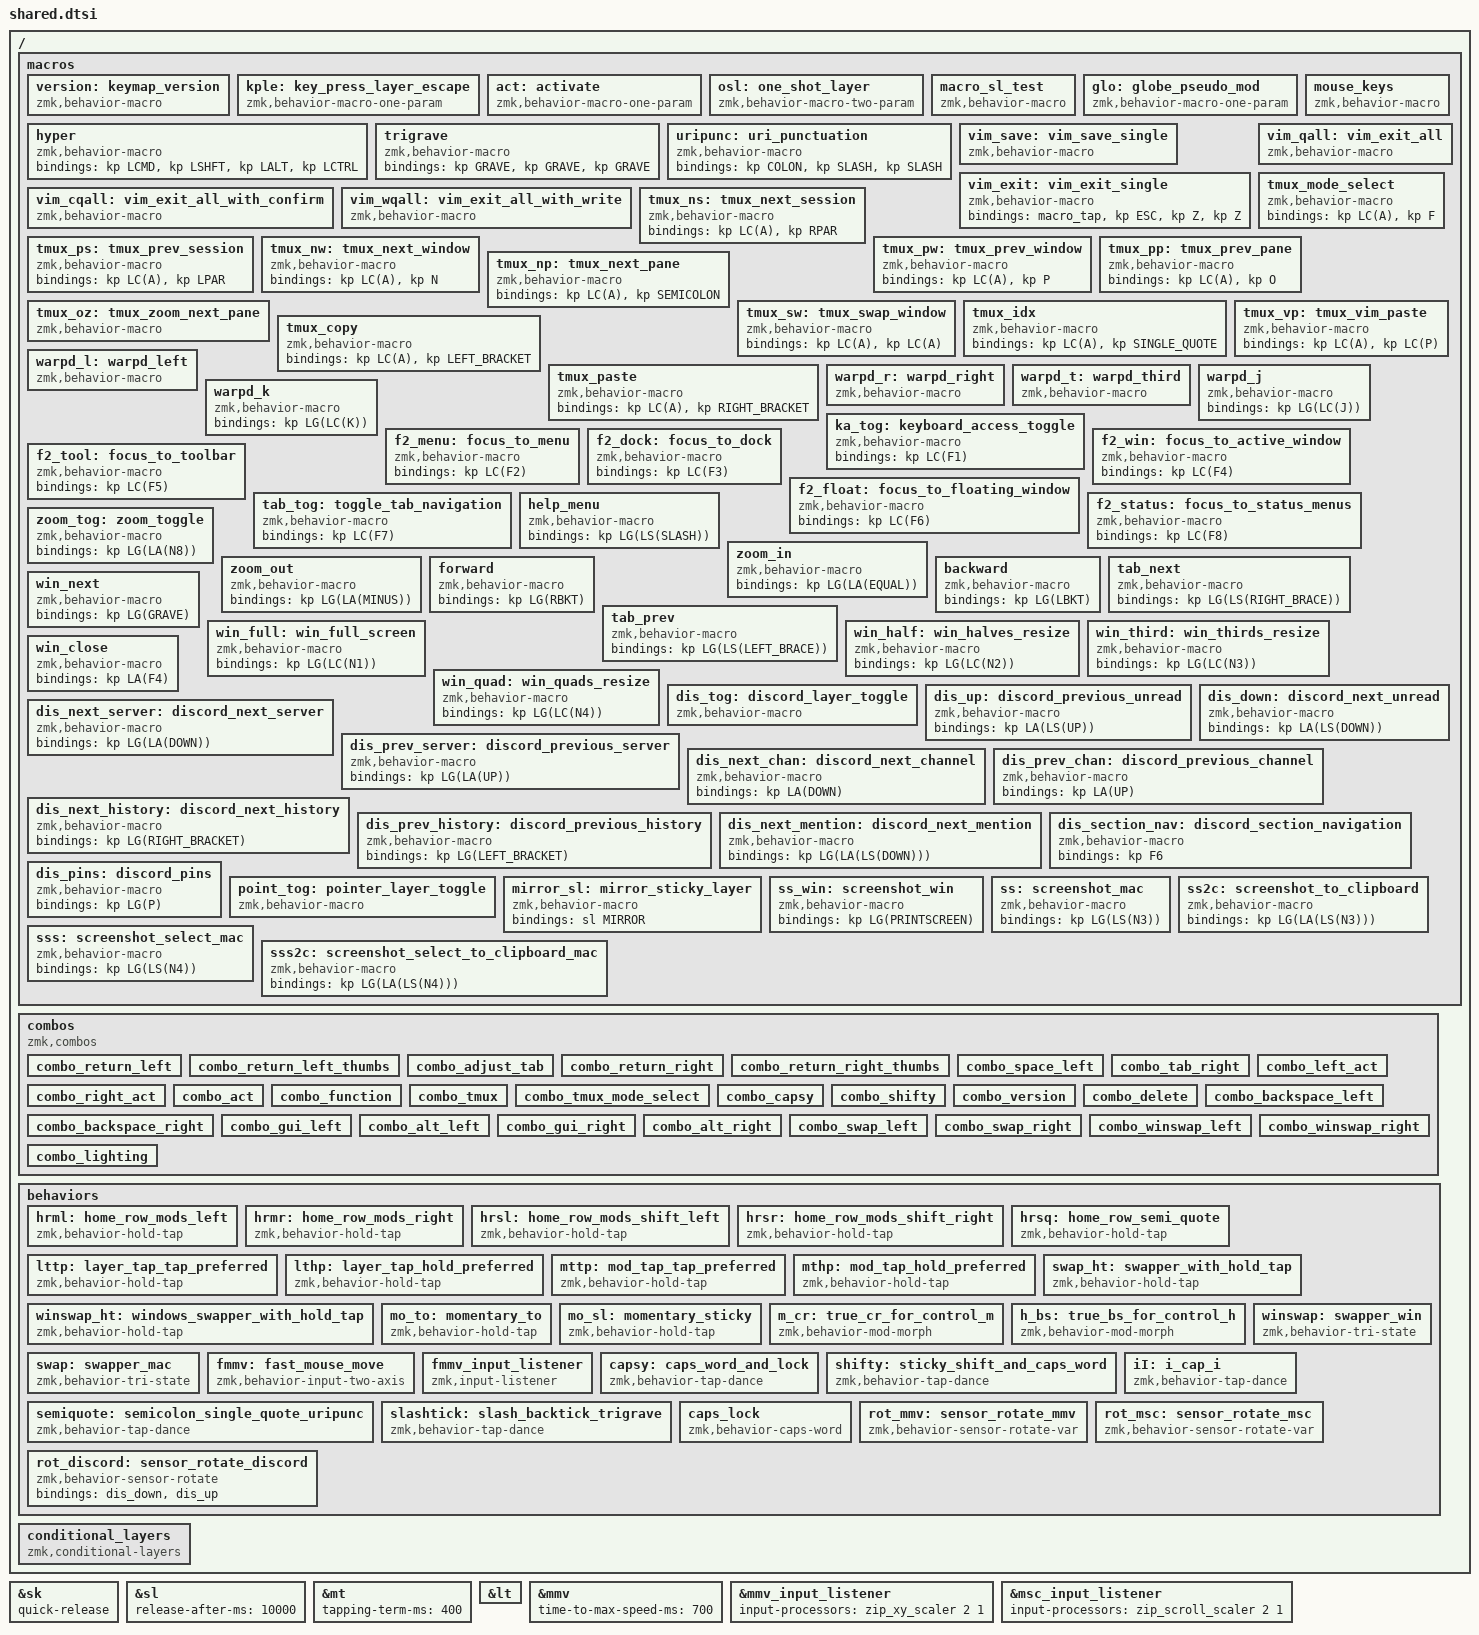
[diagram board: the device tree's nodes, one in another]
#define VER_PATCH N6
#define VER_MINOR N7
#define VER_MAJOR N3

// DEFINES {{{
#define HYPER(X) LG(LA(LC(LS(X))))
#define DISCORD_ACT LC(LS(N))
#define CARD_ACT     HYPER(A)
#define CARD_FUNC    HYPER(F)
#define CARD_DISCORD HYPER(D)
#define CARD_POINTER HYPER(P)
#define CARD_DEACTIVATE HYPER(DELETE)
#define LEFT_POSITIONS  0 1 2 3 4 5 12 13 14 15 16 17 24 25 26 27 28 29 36 37 38
#define RIGHT_POSITIONS 6 7 8 9 10 11 18 19 20 21 22 23 30 31 32 33 34 35 39 40 41

// Timing Defaults

#define CAPS_COMBO_MS 125
#define VERT_COMBO_MS 75
#define TRI_COMBO_MS  50
#define ROLL_COMBO_MS 25

// Layers
#define DEFAULT   0
#define GAMING    1
#define SYMBOLS   2
#define LNUM      3
#define NUMPAD    4
#define MEDIA     5
#define OUTPUT    6
#define ADJUST    7
#define LIGHTING  8
#define DISCORD   9
#define POINTER   10
#define MIRROR    11
#define WIN_LEFT  12
#define WIN_RIGHT 13
#define ACT       14
#define FUNCTION  15
// }}}

#include <input/processors.dtsi>

/* Key Positions
╭────────────────────────╮ ╭────────────────────────╮
│  0   1   2   3   4   5 │ │  6   7   8   9  10  11 │
│ 12  13  14  15  16  17 │ │ 18  19  20  21  22  23 │
│ 24  25  26  27  28  29 │ │ 30  31  32  33  34  35 │
╰───────────╮ 36  37  38 │ │ 39  40  41 ╭───────────╯
            ╰────────────╯ ╰────────────╯
*/
// CONFIG {{{
&sk {
    quick-release;
};

&sl {
    release-after-ms = <10000>;
};

&mt {
    tapping-term-ms = <400>;
};

&lt {
    tapping-term-ms = <400>;
    quick-tap-ms = <250>;
};

&mmv {
    time-to-max-speed-ms = <700>;
};

&mmv_input_listener {
    input-processors = <&zip_xy_scaler 2 1>;
};

&msc_input_listener {
    input-processors = <&zip_scroll_scaler 2 1>;
};

// }}}
/ {
// MACROS LAYERS {{{
    macros {
        version: keymap_version {
            compatible = "zmk,behavior-macro";
            #binding-cells = <0>;
            bindings = <&kp VER_MAJOR &kp DOT &kp VER_MINOR &kp VER_PATCH>;
        };
        kple: key_press_layer_escape {
            compatible = "zmk,behavior-macro-one-param";
            #binding-cells = <1>;
            bindings
                = <&macro_tap &kp CARD_DEACTIVATE>
                , <&macro_tap &to DEFAULT>
                , <&macro_param_1to1>
                , <&macro_tap &kp MACRO_PLACEHOLDER>
                ;
        };
        act: activate {
            compatible = "zmk,behavior-macro-one-param";
            #binding-cells = <1>;
            bindings
                = <&macro_tap &kp CARD_DEACTIVATE>
                , <&macro_tap &to DEFAULT>
                , <&macro_press &kp LSHFT &kp LCTRL>
                , <&macro_param_1to1>
                , <&macro_tap &kp MACRO_PLACEHOLDER>
                , <&macro_release &kp LSHFT &kp LCTRL>
                ;
        };
        osl: one_shot_layer {
            compatible = "zmk,behavior-macro-two-param";
            #binding-cells = <2>;
            bindings
                = <&macro_tap &kp CARD_DEACTIVATE>
                , <&macro_param_1to1>
                , <&macro_tap &kp MACRO_PLACEHOLDER>
                , <&macro_param_2to1>
                , <&macro_tap &sl MACRO_PLACEHOLDER>
                ;
        };
        macro_sl_test: macro_sl_test {
            compatible = "zmk,behavior-macro";
            #binding-cells = <0>;
            bindings
                = <&macro_tap &kp SINGLE_QUOTE>
                , <&macro_tap &sl NUMPAD>
                , <&macro_pause_for_release>
                , <&macro_tap &kp SINGLE_QUOTE>
                ;
        };
        glo: globe_pseudo_mod {
            compatible = "zmk,behavior-macro-one-param";
            #binding-cells = <1>;
            bindings
                = <&macro_press &kp GLOBE>
                , <&macro_param_1to1>
                , <&macro_tap &kp MACRO_PLACEHOLDER>
                , <&macro_release &kp GLOBE>
                ;
        };
        hyper: hyper {
            compatible = "zmk,behavior-macro";
            #binding-cells = <0>;
            bindings = <&kp LCMD &kp LSHFT &kp LALT &kp LCTRL>;
        };
        trigrave: trigrave {
            compatible = "zmk,behavior-macro";
            #binding-cells = <0>;
            bindings = <&kp GRAVE &kp GRAVE &kp GRAVE>;
        };
        uripunc: uri_punctuation {
            compatible = "zmk,behavior-macro";
            #binding-cells = <0>;
            bindings = <&kp COLON &kp SLASH &kp SLASH>;
        };
        mouse_keys: mouse_keys {
            compatible = "zmk,behavior-macro";
            #binding-cells = <0>;
            bindings = <&kp LALT &kp LALT &kp LALT &kp LALT &kp LALT>;
        };
        vim_save: vim_save_single {
            compatible = "zmk,behavior-macro";
            #binding-cells = <0>;
            bindings =
                <&macro_tap>,
                <&kp ESC &kp COLON &kp W &kp RETURN>;
        };
        vim_exit: vim_exit_single {
            compatible = "zmk,behavior-macro";
            #binding-cells = <0>;
            bindings =
                <&macro_tap>,
                <&kp ESC &kp Z &kp Z>;
        };
        vim_qall: vim_exit_all {
            compatible = "zmk,behavior-macro";
            #binding-cells = <0>;
            bindings =
                <&macro_tap>,
                <&kp ESC &kp COLON &kp Q &kp A &kp L &kp RETURN>;
        };
        vim_cqall: vim_exit_all_with_confirm {
            compatible = "zmk,behavior-macro";
            #binding-cells = <0>;
            bindings =
                <&macro_tap>,
                <&kp ESC &kp COLON &kp C &kp O &kp N &kp F &kp SPACE &kp Q &kp A &kp L &kp RETURN>;
        };
        vim_wqall: vim_exit_all_with_write {
            compatible = "zmk,behavior-macro";
            #binding-cells = <0>;
            bindings =
                <&macro_tap>,
                <&kp ESC &kp COLON &kp W &kp Q &kp A &kp L &kp RETURN>;
        };
        tmux_mode_select: tmux_mode_select {
            compatible = "zmk,behavior-macro";
            #binding-cells = <0>;
            bindings = <&kp LC(A) &kp F>;
        };
        tmux_ns: tmux_next_session {
            compatible = "zmk,behavior-macro";
            #binding-cells = <0>;
            bindings = <&kp LC(A) &kp RPAR>;
        };
        tmux_ps: tmux_prev_session {
            compatible = "zmk,behavior-macro";
            #binding-cells = <0>;
            bindings = <&kp LC(A) &kp LPAR>;
        };
        tmux_nw: tmux_next_window {
            compatible = "zmk,behavior-macro";
            #binding-cells = <0>;
            bindings = <&kp LC(A) &kp N>;
        };
        tmux_pw: tmux_prev_window {
            compatible = "zmk,behavior-macro";
            #binding-cells = <0>;
            bindings = <&kp LC(A) &kp P>;
        };
        tmux_pp: tmux_prev_pane {
            compatible = "zmk,behavior-macro";
            #binding-cells = <0>;
            bindings = <&kp LC(A) &kp O>;
        };
        tmux_np: tmux_next_pane {
            compatible = "zmk,behavior-macro";
            #binding-cells = <0>;
            bindings = <&kp LC(A) &kp SEMICOLON>;
        };
        tmux_oz: tmux_zoom_next_pane {
            compatible = "zmk,behavior-macro";
            #binding-cells = <0>;
            bindings
                = <&macro_wait_time 35>
                , <&macro_tap_time 25>
                , <&kp LC(A) &kp O>
                , <&kp LC(A) &kp Z>
                ;
        };
        tmux_sw: tmux_swap_window {
            compatible = "zmk,behavior-macro";
            #binding-cells = <0>;
            bindings
                = <&kp LC(A) &kp LC(A)>
                ;
        };
        tmux_idx: tmux_idx {
            compatible = "zmk,behavior-macro";
            #binding-cells = <0>;
            bindings
                = <&kp LC(A) &kp SINGLE_QUOTE>
                ;
        };
        tmux_copy: tmux_copy {
            compatible = "zmk,behavior-macro";
            #binding-cells = <0>;
            bindings
                = <&kp LC(A) &kp LEFT_BRACKET>
                ;
        };
        tmux_paste: tmux_paste {
            compatible = "zmk,behavior-macro";
            #binding-cells = <0>;
            bindings
                = <&kp LC(A) &kp RIGHT_BRACKET>
                ;
        };
        tmux_vp: tmux_vim_paste {
            compatible = "zmk,behavior-macro";
            #binding-cells = <0>;
            bindings
                = <&kp LC(A) &kp LC(P)>
                ;
        };
        warpd_l: warpd_left {
            compatible = "zmk,behavior-macro";
            #binding-cells = <0>;
            bindings = <&kple LG(LC(S)) &kp J &kp ESC &kp LG(LC(Y))>;
        };
        warpd_r: warpd_right {
            compatible = "zmk,behavior-macro";
            #binding-cells = <0>;
            bindings = <&kple LG(LC(S)) &kp K &kp ESC &kp LG(LC(Y))>;
        };
        warpd_t: warpd_third {
            compatible = "zmk,behavior-macro";
            #binding-cells = <0>;
            bindings = <&kple LG(LC(S)) &kp L &kp ESC &kp LG(LC(Y))>;
        };
        warpd_j: warpd_j {
            compatible = "zmk,behavior-macro";
            #binding-cells = <0>;
            bindings = <&kp LG(LC(J))>;
        };
        warpd_k: warpd_k {
            compatible = "zmk,behavior-macro";
            #binding-cells = <0>;
            bindings = <&kp LG(LC(K))>;
        };
        ka_tog: keyboard_access_toggle {
            compatible = "zmk,behavior-macro";
            #binding-cells = <0>;
            bindings = <&kp LC(F1)>;
        };
        f2_menu: focus_to_menu {
            compatible = "zmk,behavior-macro";
            #binding-cells = <0>;
            bindings = <&kp LC(F2)>;
        };
        f2_dock: focus_to_dock {
            compatible = "zmk,behavior-macro";
            #binding-cells = <0>;
            bindings = <&kp LC(F3)>;
        };
        f2_win: focus_to_active_window {
            compatible = "zmk,behavior-macro";
            #binding-cells = <0>;
            bindings = <&kp LC(F4)>;
        };
        f2_tool: focus_to_toolbar {
            compatible = "zmk,behavior-macro";
            #binding-cells = <0>;
            bindings = <&kp LC(F5)>;
        };
        f2_float: focus_to_floating_window {
            compatible = "zmk,behavior-macro";
            #binding-cells = <0>;
            bindings = <&kp LC(F6)>;
        };
        tab_tog: toggle_tab_navigation {
            compatible = "zmk,behavior-macro";
            #binding-cells = <0>;
            bindings = <&kp LC(F7)>;
        };
        f2_status: focus_to_status_menus {
            compatible = "zmk,behavior-macro";
            #binding-cells = <0>;
            bindings = <&kp LC(F8)>;
        };
        help_menu: help_menu {
            compatible = "zmk,behavior-macro";
            #binding-cells = <0>;
            bindings = <&kp LG(LS(SLASH))>;
        };
        zoom_tog: zoom_toggle {
            compatible = "zmk,behavior-macro";
            #binding-cells = <0>;
            bindings = <&kp LG(LA(N8))>;
        };
        zoom_in: zoom_in {
            compatible = "zmk,behavior-macro";
            #binding-cells = <0>;
            bindings = <&kp LG(LA(EQUAL))>;
        };
        zoom_out: zoom_out {
            compatible = "zmk,behavior-macro";
            #binding-cells = <0>;
            bindings = <&kp LG(LA(MINUS))>;
        };
        forward: forward {
            compatible = "zmk,behavior-macro";
            #binding-cells = <0>;
            bindings = <&kp LG(RBKT)>;
        };
        backward: backward {
            compatible = "zmk,behavior-macro";
            #binding-cells = <0>;
            bindings = <&kp LG(LBKT)>;
        };
        tab_next: tab_next {
            compatible = "zmk,behavior-macro";
            #binding-cells = <0>;
            bindings = <&kp LG(LS(RIGHT_BRACE))>;
        };
        tab_prev: tab_prev {
            compatible = "zmk,behavior-macro";
            #binding-cells = <0>;
            bindings = <&kp LG(LS(LEFT_BRACE))>;
        };
        win_next: win_next {
            compatible = "zmk,behavior-macro";
            #binding-cells = <0>;
            bindings = <&kp LG(GRAVE)>;
        };
        win_full: win_full_screen {
            compatible = "zmk,behavior-macro";
            #binding-cells = <0>;
            bindings = <&kp LG(LC(N1))>;
        };
        win_half: win_halves_resize {
            compatible = "zmk,behavior-macro";
            #binding-cells = <0>;
            bindings = <&kp LG(LC(N2))>;
        };
        win_third: win_thirds_resize {
            compatible = "zmk,behavior-macro";
            #binding-cells = <0>;
            bindings = <&kp LG(LC(N3))>;
        };
        win_quad: win_quads_resize {
            compatible = "zmk,behavior-macro";
            #binding-cells = <0>;
            bindings = <&kp LG(LC(N4))>;
        };
        win_close: win_close {
            compatible = "zmk,behavior-macro";
            #binding-cells = <0>;
            bindings = <&kp LA(F4)>;
        };
        dis_tog: discord_layer_toggle {
            compatible = "zmk,behavior-macro";
            #binding-cells = <0>;
            bindings
                = <&macro_tap &kp CARD_DISCORD>
                , <&macro_tap &tog DISCORD>
                , <&macro_tap &kp DISCORD_ACT>
                ;
        };
        dis_up: discord_previous_unread {
            compatible = "zmk,behavior-macro";
            #binding-cells = <0>;
            bindings = <&kp LA(LS(UP))>;
        };
        dis_down: discord_next_unread {
            compatible = "zmk,behavior-macro";
            #binding-cells = <0>;
            bindings = <&kp LA(LS(DOWN))>;
        };
        dis_next_server: discord_next_server {
            compatible = "zmk,behavior-macro";
            #binding-cells = <0>;
            bindings = <&kp LG(LA(DOWN))>;
        };
        dis_prev_server: discord_previous_server {
            compatible = "zmk,behavior-macro";
            #binding-cells = <0>;
            bindings = <&kp LG(LA(UP))>;
        };
        dis_next_chan: discord_next_channel {
            compatible = "zmk,behavior-macro";
            #binding-cells = <0>;
            bindings = <&kp LA(DOWN)>;
        };
        dis_prev_chan: discord_previous_channel {
            compatible = "zmk,behavior-macro";
            #binding-cells = <0>;
            bindings = <&kp LA(UP)>;
        };
        dis_next_history: discord_next_history {
            compatible = "zmk,behavior-macro";
            #binding-cells = <0>;
            bindings = <&kp LG(RIGHT_BRACKET)>;
        };
        dis_prev_history: discord_previous_history {
            compatible = "zmk,behavior-macro";
            #binding-cells = <0>;
            bindings = <&kp LG(LEFT_BRACKET)>;
        };
        dis_next_mention: discord_next_mention {
            compatible = "zmk,behavior-macro";
            #binding-cells = <0>;
            bindings = <&kp LG(LA(LS(DOWN)))>;
        };
        dis_section_nav: discord_section_navigation {
            compatible = "zmk,behavior-macro";
            #binding-cells = <0>;
            bindings = <&kp F6>;
        };
        dis_pins: discord_pins {
            compatible = "zmk,behavior-macro";
            #binding-cells = <0>;
            bindings = <&kp LG(P)>;
        };
        point_tog: pointer_layer_toggle {
            compatible = "zmk,behavior-macro";
            #binding-cells = <0>;
            bindings
                = <&macro_tap &kp CARD_POINTER>
                , <&macro_tap &tog POINTER>
                ;
        };
        mirror_sl: mirror_sticky_layer {
            compatible = "zmk,behavior-macro";
            #binding-cells = <0>;
            bindings = <&sl MIRROR>;
        };
        ss_win: screenshot_win {
            compatible = "zmk,behavior-macro";
            #binding-cells = <0>;
            bindings = <&kp LG(PRINTSCREEN)>;
        };
        ss: screenshot_mac {
            compatible = "zmk,behavior-macro";
            #binding-cells = <0>;
            bindings = <&kp LG(LS(N3))>;
        };
        ss2c: screenshot_to_clipboard {
            compatible = "zmk,behavior-macro";
            #binding-cells = <0>;
            bindings = <&kp LG(LA(LS(N3)))>;
        };
        sss: screenshot_select_mac {
            compatible = "zmk,behavior-macro";
            #binding-cells = <0>;
            bindings = <&kp LG(LS(N4))>;
        };
        sss2c: screenshot_select_to_clipboard_mac {
            compatible = "zmk,behavior-macro";
            #binding-cells = <0>;
            bindings = <&kp LG(LA(LS(N4)))>;
        };

    };
// }}}
// COMBOS {{{
//   ╭────────────────────────╮ ╭────────────────────────╮
//   │  0   1   2   3   4   5 │ │  6   7   8   9  10  11 │
//   │ 12  13  14  15  16  17 │ │ 18  19  20  21  22  23 │
//   │ 24  25  26  27  28  29 │ │ 30  31  32  33  34  35 │
//   ╰───────────╮ 36  37  38 │ │ 39  40  41 ╭───────────╯
//               ╰────────────╯ ╰────────────╯
    combos {
        compatible = "zmk,combos";
        combo_return_left: combo_return_left {
            timeout-ms = <VERT_COMBO_MS>;
            slow-release;
            key-positions = <5 17>;
            bindings = <&kp RETURN>;
            layers = <DEFAULT GAMING>;
        };
        combo_return_left_thumbs: combo_return_left_thumbs {
            timeout-ms = <VERT_COMBO_MS>;
            key-positions = <37 38>;
            bindings = <&lthp ADJUST RETURN>;
            layers = <DEFAULT GAMING>;
        };
        combo_adjust_tab: combo_adjust_tab {
            timeout-ms = <VERT_COMBO_MS>;
            key-positions = <38 39>;
            bindings = <&lttp ADJUST TAB>;
            layers = <DEFAULT GAMING>;
        };
        combo_return_right: combo_return_right {
            timeout-ms = <VERT_COMBO_MS>;
            slow-release;
            key-positions = <6 18>;
            bindings = <&kp RETURN>;
            layers = <DEFAULT GAMING>;
        };
        combo_return_right_thumbs: combo_return_right_thumbs {
            timeout-ms = <VERT_COMBO_MS>;
            key-positions = <39 40>;
            bindings = <&lthp OUTPUT RETURN>;
            layers = <DEFAULT GAMING>;
        };
        combo_space_left: combo_space_left {
            timeout-ms = <VERT_COMBO_MS>;
            slow-release;
            key-positions = <17 29>;
            bindings = <&kp SPACE>;
            layers = <DEFAULT GAMING>;
        };
        combo_tab_right: combo_tab_right {
            timeout-ms = <VERT_COMBO_MS>;
            slow-release;
            key-positions = <18 30>;
            bindings = <&kp TAB>;
            layers = <DEFAULT GAMING>;
        };
        combo_left_act: combo_left_act {
            timeout-ms = <VERT_COMBO_MS>;
            slow-release;
            key-positions = <1 16>;
            bindings = <&osl CARD_ACT ACT>;
            layers = <DEFAULT>;
        };
        combo_right_act: combo_right_act {
            timeout-ms = <VERT_COMBO_MS>;
            slow-release;
            key-positions = <10 19>;
            bindings = <&osl CARD_ACT ACT>;
            layers = <DEFAULT>;
        };
        combo_act: combo_act {
            timeout-ms = <ROLL_COMBO_MS>;
            slow-release;
            key-positions = <37 40>;
            bindings = <&osl CARD_ACT ACT>;
            layers = <DEFAULT POINTER DISCORD>;
        };
        combo_function: combo_function {
            timeout-ms = <ROLL_COMBO_MS>;
            slow-release;
            key-positions = <5 6>;
            bindings = <&osl CARD_FUNC FUNCTION>;
            layers = <DEFAULT>;
        };
        combo_tmux: combo_tmux {
            timeout-ms = <TRI_COMBO_MS>;
            slow-release;
            key-positions = <7 8 9>;
            bindings = <&kp LC(A)>;
            layers = <DEFAULT>;
        };
        combo_tmux_mode_select: combo_tmux_mode_select {
            timeout-ms = <TRI_COMBO_MS>;
            slow-release;
            key-positions = <2 3 4>;
            bindings = <&tmux_mode_select>;
            layers = <DEFAULT>;
        };
        combo_capsy: combo_capsy {
            timeout-ms = <CAPS_COMBO_MS>;
            slow-release;
            key-positions = <16 19>;
            bindings = <&capsy>;
            layers = <DEFAULT GAMING>;
        };
        combo_shifty: combo_shifty {
            timeout-ms = <CAPS_COMBO_MS>;
            slow-release;
            key-positions = <13 22>;
            bindings = <&shifty>;
            layers = <DEFAULT GAMING>;
        };
        combo_version: combo_version {
            timeout-ms = <ROLL_COMBO_MS>;
            key-positions = <1 2>;
            bindings = <&version>;
            layers = <DEFAULT>;
        };
        combo_delete: combo_delete {
            timeout-ms = <ROLL_COMBO_MS>;
            slow-release;
            key-positions = <9 10>;
            bindings = <&kp DELETE>;
            layers = <DEFAULT GAMING>;
        };
        combo_backspace_left: combo_backspace_left {
            timeout-ms = <VERT_COMBO_MS>;
            slow-release;
            key-positions = <1 13>;
            bindings = <&kp BACKSPACE>;
            layers = <DEFAULT GAMING>;
        };
        combo_backspace_right: combo_backspace_right {
            timeout-ms = <VERT_COMBO_MS>;
            slow-release;
            key-positions = <10 22>;
            bindings = <&kp BACKSPACE>;
            layers = <DEFAULT GAMING>;
        };
        combo_gui_left: combo_gui_left {
            timeout-ms = <ROLL_COMBO_MS>;
            key-positions = <25 26>;
            bindings = <&kp LGUI>;
            layers = <DEFAULT GAMING>;
        };
        combo_alt_left: combo_alt_left {
            timeout-ms = <ROLL_COMBO_MS>;
            key-positions = <13 25>;
            bindings = <&kp LALT>;
            layers = <DEFAULT GAMING>;
        };
        combo_gui_right: combo_gui_right {
            timeout-ms = <ROLL_COMBO_MS>;
            key-positions = <33 34>;
            bindings = <&kp LGUI>;
            layers = <DEFAULT GAMING>;
        };
        combo_alt_right: combo_alt_right {
            timeout-ms = <ROLL_COMBO_MS>;
            key-positions = <22 34>;
            bindings = <&kp LALT>;
            layers = <DEFAULT GAMING>;
        };
        combo_swap_left: combo_swap_left {
            timeout-ms = <ROLL_COMBO_MS>;
            key-positions = <16 25>;
            bindings = <&swap_ht 0 LG(TAB)>;
            layers = <DEFAULT DISCORD POINTER MIRROR>;
        };
        combo_swap_right: combo_swap_right {
            timeout-ms = <ROLL_COMBO_MS>;
            key-positions = <19 34>;
            bindings = <&swap_ht 0 LG(TAB)>;
            layers = <DEFAULT DISCORD POINTER MIRROR>;
        };
        combo_winswap_left: combo_winswap_left {
            timeout-ms = <ROLL_COMBO_MS>;
            key-positions = <25 28>;
            bindings = <&winswap_ht 0 LA(TAB)>;
            layers = <DEFAULT DISCORD POINTER MIRROR>;
        };
        combo_winswap_right: combo_winswap_right {
            timeout-ms = <ROLL_COMBO_MS>;
            key-positions = <31 34>;
            bindings = <&winswap_ht 0 LA(TAB)>;
            layers = <DEFAULT DISCORD POINTER MIRROR>;
        };
       combo_lighting: combo_lighting {
           timeout-ms = <VERT_COMBO_MS>;
           slow-release;
           key-positions = <1 10>;
           bindings = <&mo LIGHTING>;
           layers = <DEFAULT>;
       };

    };

// }}}
// BEHAVIORS {{{
    behaviors {
        hrml: home_row_mods_left {
            compatible = "zmk,behavior-hold-tap";
            #binding-cells = <2>;
            tapping-term-ms = <200>;
            quick-tap-ms = <150>;
            flavor = "balanced";
            //require-prior-idle-ms = <125>;
            hold-trigger-key-positions = < RIGHT_POSITIONS >;
            //hold-trigger-on-release; // delay positional check until key release
            bindings =
                <&kp>,
                <&kp>;
        };
        hrmr: home_row_mods_right {
            compatible = "zmk,behavior-hold-tap";
            #binding-cells = <2>;
            tapping-term-ms = <200>;
            quick-tap-ms = <150>;
            flavor = "balanced";
            //require-prior-idle-ms = <125>;
            hold-trigger-key-positions = < LEFT_POSITIONS >;
            //hold-trigger-on-release; // delay positional check until key release
            bindings =
                <&kp>,
                <&kp>;
        };
        hrsl: home_row_mods_shift_left {
            compatible = "zmk,behavior-hold-tap";
            #binding-cells = <2>;
            tapping-term-ms = <175>;
            quick-tap-ms = <150>;
            flavor = "tap-preferred";
            //require-prior-idle-ms = <125>;
            hold-trigger-key-positions = < RIGHT_POSITIONS >;
            //hold-trigger-on-release; // delay positional check until key release
            bindings =
                <&kp>,
                <&kp>;
        };
        hrsr: home_row_mods_shift_right {
            compatible = "zmk,behavior-hold-tap";
            #binding-cells = <2>;
            tapping-term-ms = <175>;
            quick-tap-ms = <150>;
            flavor = "tap-preferred";
            //require-prior-idle-ms = <125>;
            hold-trigger-key-positions = < LEFT_POSITIONS >;
            //hold-trigger-on-release; // delay positional check until key release
            bindings =
                <&kp>,
                <&kp>;
        };
        /omit-if-no-ref/ hrsq: home_row_semi_quote {
            compatible = "zmk,behavior-hold-tap";
            #binding-cells = <2>;
            tapping-term-ms = <200>;
            quick-tap-ms = <150>;
            flavor = "balanced";
            require-prior-idle-ms = <125>;
            //hold-trigger-key-positions = <list of all lhs keys>;
            //hold-trigger-on-release; // delay positional check until key release
            bindings =
                <&kp>,
                <&semiquote>;
        };
        lttp: layer_tap_tap_preferred {
            compatible = "zmk,behavior-hold-tap";
            #binding-cells = <2>;
            tapping-term-ms = <300>;
            quick-tap-ms = <150>;
            //require-prior-idle-ms = <125>;
            flavor = "tap-preferred";
            bindings =
                <&mo>,
                <&kp>;
        };
        lthp: layer_tap_hold_preferred {
            compatible = "zmk,behavior-hold-tap";
            #binding-cells = <2>;
            tapping-term-ms = <300>;
            quick-tap-ms = <150>;
            //require-prior-idle-ms = <125>;
            flavor = "hold-preferred";
            bindings =
                <&mo>,
                <&kp>;
        };
        mttp: mod_tap_tap_preferred {
            compatible = "zmk,behavior-hold-tap";
            #binding-cells = <2>;
            tapping-term-ms = <300>;
            quick-tap-ms = <150>;
            //require-prior-idle-ms = <125>;
            flavor = "tap-preferred";
            bindings =
                <&kp>,
                <&kp>;
        };
        mthp: mod_tap_hold_preferred {
            compatible = "zmk,behavior-hold-tap";
            #binding-cells = <2>;
            tapping-term-ms = <300>;
            quick-tap-ms = <150>;
            //require-prior-idle-ms = <125>;
            flavor = "hold-preferred";
            bindings =
                <&kp>,
                <&kp>;
        };
        swap_ht: swapper_with_hold_tap {
            compatible = "zmk,behavior-hold-tap";
            #binding-cells = <2>;
            tapping-term-ms = <300>;
            quick-tap-ms = <150>;
            flavor = "tap-preferred";
            bindings =
                <&swap>,
                <&kple>;
        };
        winswap_ht: windows_swapper_with_hold_tap {
            compatible = "zmk,behavior-hold-tap";
            #binding-cells = <2>;
            tapping-term-ms = <300>;
            quick-tap-ms = <150>;
            flavor = "tap-preferred";
            bindings =
                <&winswap>,
                <&kple>;
        };
        mo_to: momentary_to {
            compatible = "zmk,behavior-hold-tap";
            #binding-cells = <2>;
            tapping-term-ms = <300>;
            quick-tap-ms = <150>;
            flavor = "hold-preferred";
            bindings =
                <&mo>,
                <&to>;
        };
        mo_sl: momentary_sticky {
            compatible = "zmk,behavior-hold-tap";
            #binding-cells = <2>;
            tapping-term-ms = <300>;
            quick-tap-ms = <150>;
            flavor = "hold-preferred";
            bindings =
                <&mo>,
                <&sl>;
        };
        m_cr: true_cr_for_control_m {
            compatible = "zmk,behavior-mod-morph";
            #binding-cells = <0>;
            bindings =
                <&kp M>,
                <&kp RETURN>;
            mods = <(MOD_LCTL|MOD_RCTL)>;
        };
        h_bs: true_bs_for_control_h {
            compatible = "zmk,behavior-mod-morph";
            #binding-cells = <0>;
            bindings =
                <&kp H>,
                <&kp BACKSPACE>;
            mods = <(MOD_LCTL|MOD_RCTL)>;
        };
        winswap: swapper_win {
            compatible = "zmk,behavior-tri-state";
            #binding-cells = <0>;
            bindings =
                <&kt LALT>,
                <&kp TAB>,
                <&kt LALT>;
            ignored-key-positions = <1 25 28 10 31 34 18 19 20 21 40>;
            ignored-layers = <DEFAULT NUMPAD>;
        };
        swap: swapper_mac {
            compatible = "zmk,behavior-tri-state";
            #binding-cells = <0>;
            bindings =
                <&kt LGUI>,
                <&kp TAB>,
                <&kt LGUI>;
            // must include activating combo keys too (16 25, 19 34) or else tri-state will complete immediately for Mac
            // include hjkl (18 19 20 21) and nav layer activation (40) for navigation
            // include mode keys: h to hide (18), q to quit (1)
            // include lhs arrow key shortcuts: 36, 37, 38
            ignored-key-positions = <1 16 18 19 20 21 25 34 36 37 38 40>;
            ignored-layers = <DEFAULT NUMPAD>;
        };
        /omit-if-no-ref/ fmmv: fast_mouse_move {
            compatible = "zmk,behavior-input-two-axis";
            #binding-cells = <1>;
            x-input-code = <INPUT_REL_X>;
            y-input-code = <INPUT_REL_Y>;
            time-to-max-speed-ms = <200>;
            acceleration-exponent = <1>;
        };
        fmmv_input_listener {
            compatible = "zmk,input-listener";
            input-processors = <&zip_xy_scaler 6 1>;
            device = <&fmmv>;
        };
        capsy: caps_word_and_lock {
            compatible = "zmk,behavior-tap-dance";
            #binding-cells = <0>;
            tapping-term-ms = <250>;
            bindings
                = <&caps_word>
                , <&caps_lock>
                ;
        };
        shifty: sticky_shift_and_caps_word {
            compatible = "zmk,behavior-tap-dance";
            #binding-cells = <0>;
            tapping-term-ms = <250>;
            bindings
                = <&sk LEFT_SHIFT>
                , <&caps_word>
                ;
        };
        iI: i_cap_i {
            compatible = "zmk,behavior-tap-dance";
            #binding-cells = <0>;
            tapping-term-ms = <250>;
            bindings = <&kp I>, <&kp LS(I)>;
        };
        /omit-if-no-ref/ semiquote: semicolon_single_quote_uripunc {
            compatible = "zmk,behavior-tap-dance";
            #binding-cells = <0>;
            tapping-term-ms = <250>;
            bindings = <&kp SEMICOLON>, <&kp SINGLE_QUOTE>, <&uripunc>;
        };
        /omit-if-no-ref/ slashtick: slash_backtick_trigrave {
            compatible = "zmk,behavior-tap-dance";
            #binding-cells = <0>;
            tapping-term-ms = <250>;
            bindings = <&kp SLASH>, <&kp GRAVE>, <&trigrave>;
        };
        caps_lock: caps_lock {
            compatible = "zmk,behavior-caps-word";
            #binding-cells = <0>;
            continue-list = <
SPACE SLASH COLON RETURN COMMA AMPERSAND ASTERISK TILDE BACKSLASH LESS_THAN GREATER_THAN LEFT_PARENTHESIS RIGHT_PARENTHESIS DOUBLE_QUOTES DOT DOLLAR PERCENT CARET TAB MINUS EQUAL LEFT_BRACE RIGHT_BRACE SINGLE_QUOTE EXCLAMATION AT POUND PIPE UNDERSCORE PLUS LEFT_BRACKET RIGHT_BRACKET GRAVE
            >;
        };
        /omit-if-no-ref/ rot_mmv: sensor_rotate_mmv {
            compatible = "zmk,behavior-sensor-rotate-var";
            #sensor-binding-cells = <2>;
            tap-ms = <75>;
            bindings = <&fmmv>, <&fmmv>;
        };
        /omit-if-no-ref/ rot_msc: sensor_rotate_msc {
            compatible = "zmk,behavior-sensor-rotate-var";
            #sensor-binding-cells = <2>;
            tap-ms = <75>;
            bindings = <&msc>, <&msc>;
        };
        /omit-if-no-ref/ rot_discord: sensor_rotate_discord {
            compatible = "zmk,behavior-sensor-rotate";
            #sensor-binding-cells = <0>;
            bindings = <&dis_down>, <&dis_up>;
        };

    };
// }}}
// CONDITIONAL LAYERS {{{
    conditional_layers {
        compatible = "zmk,conditional-layers";

        // replaced with combo layer-tap
        //to_adjust {
        //    if-layers = <SYMBOLS MEDIA>;
        //    then-layer = <ADJUST>;
        //};

        // provided by combo_lighting due to transparent layer issues
        //to_lighting {
        //    if-layers = <WIN_LEFT WIN_RIGHT>;
        //    then-layer = <LIGHTING>;
        //};

        // replaced with combo layer-tap
        //to_discord {f
        //    if-layers = <NUMPAD MEDIA>;
        //    then-layer = <DISCORD>;
        //};

    };
// }}}
};
/* vim: set ft=dts: */
